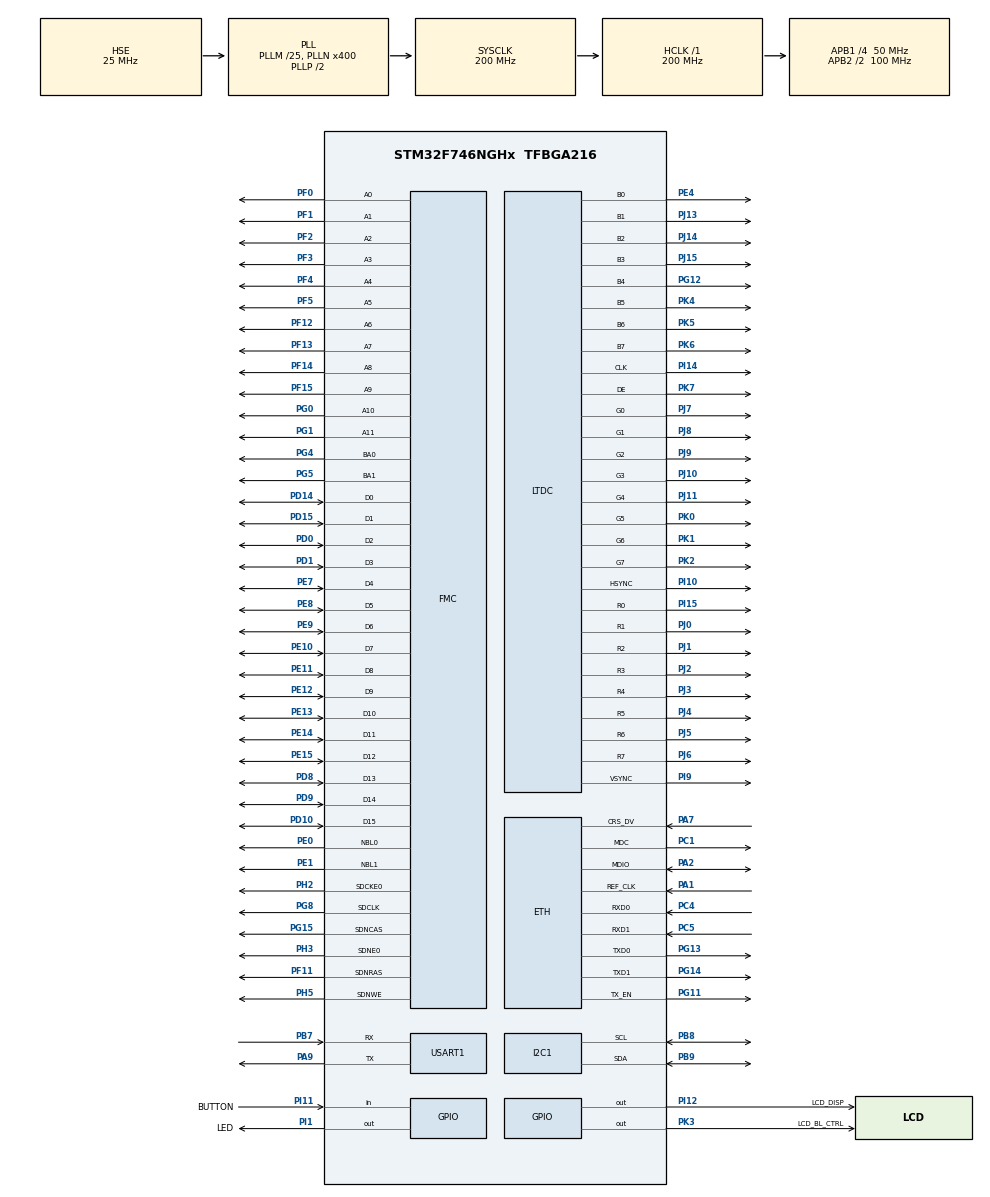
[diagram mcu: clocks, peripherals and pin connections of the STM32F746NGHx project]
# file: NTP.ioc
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ETH.MACAddr=00\:80\:E1\:00\:00\:44
ETH.MediaInterface=HAL_ETH_RMII_MODE
ETH.PhyAddress=0
FREERTOS.Tasks01=app,0,2048,app_main,As weak,NULL,Dynamic,NULL,NULL
FREERTOS.configTOTAL_HEAP_SIZE=15360
FREERTOS.configUSE_NEWLIB_REENTRANT=1
I2C1.Timing=0x00C0EAFF
LTDC.ActiveH=272
LTDC.ActiveW=480
LTDC.Alpha_L0=255
LTDC.Alpha_L1=255
LTDC.BlendingFactor1_L0=LTDC_BLENDING_FACTOR1_PAxCA
LTDC.BlendingFactor1_L1=LTDC_BLENDING_FACTOR1_PAxCA
LTDC.BlendingFactor2_L0=LTDC_BLENDING_FACTOR2_PAxCA
LTDC.BlendingFactor2_L1=LTDC_BLENDING_FACTOR2_PAxCA
LTDC.Green=255
LTDC.HBP=13
LTDC.HFP=32
LTDC.HSync=41
LTDC.ImageHeight_L0=272
LTDC.ImageHeight_L1=272
LTDC.ImageWidth_L0=480
LTDC.ImageWidth_L1=480
LTDC.PixelFormat_L0=LTDC_PIXEL_FORMAT_ARGB1555
LTDC.PixelFormat_L1=LTDC_PIXEL_FORMAT_ARGB1555
LTDC.VSync=10
LTDC.WindowX1_L0=480
LTDC.WindowX1_L1=480
LTDC.WindowY1_L0=272
LTDC.WindowY1_L1=272
LWIP.BSP.number=1
LWIP.LWIP_DNS=1
LWIP.Version=v2.1.2_Cube
LWIP0.BSP.STBoard=false
LWIP0.BSP.api=BSP_COMPONENT_DRIVER
LWIP0.BSP.component=LAN8742
LWIP0.BSP.instance=LAN8742
LWIP0.BSP.name=Driver_PHY
LWIP0.BSP.semaphore=S_LAN8742
LWIP0.BSP.solution=LAN8742
Mcu.Family=STM32F7
Mcu.Name=STM32F746NGHx
Mcu.Package=TFBGA216
NVIC.ETH_IRQn=true\:5\:0\:false\:false\:true\:true\:false\:true\:true
NVIC.PriorityGroup=NVIC_PRIORITYGROUP_4
NVIC.TIM1_UP_TIM10_IRQn=true\:15\:0\:false\:false\:true\:false\:false\:true\:true
NVIC.TimeBase=TIM1_UP_TIM10_IRQn
NVIC.TimeBaseIP=TIM1
PA1.Mode=RMII
PA1.Signal=ETH_REF_CLK
PA2.Mode=RMII
PA2.Signal=ETH_MDIO
PA7.Mode=RMII
PA7.Signal=ETH_CRS_DV
PA9.Mode=Asynchronous
PA9.Signal=USART1_TX
PB7.Mode=Asynchronous
PB7.Signal=USART1_RX
PB8.Mode=I2C
PB8.Signal=I2C1_SCL
PB9.Mode=I2C
PB9.Signal=I2C1_SDA
PC1.Mode=RMII
PC1.Signal=ETH_MDC
PC14/OSC32_IN.Mode=LSE-External-Oscillator
PC14/OSC32_IN.Signal=RCC_OSC32_IN
PC15/OSC32_OUT.Mode=LSE-External-Oscillator
PC15/OSC32_OUT.Signal=RCC_OSC32_OUT
PC4.Mode=RMII
PC4.Signal=ETH_RXD0
PC5.Mode=RMII
PC5.Signal=ETH_RXD1
PD0.Signal=FMC_D2_DA2
PD1.Signal=FMC_D3_DA3
PD10.Signal=FMC_D15_DA15
PD14.Signal=FMC_D0_DA0
PD15.Signal=FMC_D1_DA1
PD8.Signal=FMC_D13_DA13
PD9.Signal=FMC_D14_DA14
PE0.Signal=FMC_NBL0
PE1.Signal=FMC_NBL1
PE10.Signal=FMC_D7_DA7
PE11.Signal=FMC_D8_DA8
PE12.Signal=FMC_D9_DA9
PE13.Signal=FMC_D10_DA10
PE14.Signal=FMC_D11_DA11
PE15.Signal=FMC_D12_DA12
PE4.Mode=RGB888
PE4.Signal=LTDC_B0
PE7.Signal=FMC_D4_DA4
PE8.Signal=FMC_D5_DA5
PE9.Signal=FMC_D6_DA6
PF0.Signal=FMC_A0
PF1.Signal=FMC_A1
PF11.Signal=FMC_SDNRAS
PF12.Signal=FMC_A6
PF13.Signal=FMC_A7
PF14.Signal=FMC_A8
PF15.Signal=FMC_A9
PF2.Signal=FMC_A2
PF3.Signal=FMC_A3
PF4.Signal=FMC_A4
PF5.Signal=FMC_A5
PG0.Signal=FMC_A10
PG1.Signal=FMC_A11
PG11.Mode=RMII
PG11.Signal=ETH_TX_EN
PG12.Mode=RGB888
PG12.Signal=LTDC_B4
PG13.Mode=RMII
PG13.Signal=ETH_TXD0
PG14.Mode=RMII
PG14.Signal=ETH_TXD1
PG15.Signal=FMC_SDNCAS
PG4.Signal=FMC_A14_BA0
PG5.Signal=FMC_A15_BA1
PG8.Signal=FMC_SDCLK
PH0/OSC_IN.Mode=HSE-External-Oscillator
PH0/OSC_IN.Signal=RCC_OSC_IN
PH1/OSC_OUT.Mode=HSE-External-Oscillator
PH1/OSC_OUT.Signal=RCC_OSC_OUT
PH2.Mode=SdramChipSelect1_1
PH2.Signal=FMC_SDCKE0
PH3.Mode=SdramChipSelect1_1
PH3.Signal=FMC_SDNE0
PH5.Signal=FMC_SDNWE
PI1.GPIO_Label=LED
PI1.Signal=GPIO_Output
PI10.Mode=RGB888
PI10.Signal=LTDC_HSYNC
PI11.GPIO_Label=BUTTON
PI11.Signal=GPIO_Input
PI12.GPIO_Label=LCD_DISP
PI12.Signal=GPIO_Output
PI14.Mode=RGB888
PI14.Signal=LTDC_CLK
PI15.Mode=RGB888
PI15.Signal=LTDC_R0
PI9.Mode=RGB888
PI9.Signal=LTDC_VSYNC
PJ0.Mode=RGB888
PJ0.Signal=LTDC_R1
PJ1.Mode=RGB888
PJ1.Signal=LTDC_R2
PJ10.Mode=RGB888
PJ10.Signal=LTDC_G3
PJ11.Mode=RGB888
PJ11.Signal=LTDC_G4
PJ13.Mode=RGB888
PJ13.Signal=LTDC_B1
PJ14.Mode=RGB888
PJ14.Signal=LTDC_B2
PJ15.Mode=RGB888
PJ15.Signal=LTDC_B3
PJ2.Mode=RGB888
PJ2.Signal=LTDC_R3
PJ3.Mode=RGB888
PJ3.Signal=LTDC_R4
PJ4.Mode=RGB888
PJ4.Signal=LTDC_R5
PJ5.Mode=RGB888
PJ5.Signal=LTDC_R6
PJ6.Mode=RGB888
PJ6.Signal=LTDC_R7
PJ7.Mode=RGB888
PJ7.Signal=LTDC_G0
PJ8.Mode=RGB888
PJ8.Signal=LTDC_G1
PJ9.Mode=RGB888
PJ9.Signal=LTDC_G2
PK0.Mode=RGB888
PK0.Signal=LTDC_G5
PK1.Mode=RGB888
PK1.Signal=LTDC_G6
PK2.Mode=RGB888
PK2.Signal=LTDC_G7
PK3.GPIO_Label=LCD_BL_CTRL
PK3.Signal=GPIO_Output
PK4.Mode=RGB888
PK4.Signal=LTDC_B5
PK5.Mode=RGB888
PK5.Signal=LTDC_B6
PK6.Mode=RGB888
PK6.Signal=LTDC_B7
PK7.Mode=RGB888
PK7.Signal=LTDC_DE
ProjectManager.HeapSize=0x200
ProjectManager.StackSize=0x400
ProjectManager.TargetToolchain=STM32CubeIDE
RCC.AHBFreq_Value=200000000
RCC.APB1CLKDivider=RCC_HCLK_DIV4
RCC.APB1Freq_Value=50000000
RCC.APB1TimFreq_Value=100000000
RCC.APB2CLKDivider=RCC_HCLK_DIV2
RCC.APB2Freq_Value=100000000
RCC.APB2TimFreq_Value=200000000
RCC.CortexFreq_Value=200000000
RCC.HCLKFreq_Value=200000000
RCC.HSE_VALUE=25000000
RCC.HSI_VALUE=16000000
RCC.PLLM=25
RCC.PLLN=400
RCC.PLLSAIR=5
RCC.PLLSAIRDiv=RCC_PLLSAIDIVR_4
RCC.PLLSourceVirtual=RCC_PLLSOURCE_HSE
RCC.RTCClockSelection=RCC_RTCCLKSOURCE_LSE
RCC.SYSCLKFreq_VALUE=200000000
RCC.SYSCLKSource=RCC_SYSCLKSOURCE_PLLCLK
RCC.USBFreq_Value=200000000
RCC.VCOOutputFreq_Value=400000000
SH.FMC_A0.0=FMC_A0,12b-sda1
SH.FMC_A1.0=FMC_A1,12b-sda1
SH.FMC_A10.0=FMC_A10,12b-sda1
SH.FMC_A11.0=FMC_A11,12b-sda1
SH.FMC_A14_BA0.0=FMC_BA0,FourSdramBanks1
SH.FMC_A15_BA1.0=FMC_BA1,FourSdramBanks1
SH.FMC_A2.0=FMC_A2,12b-sda1
SH.FMC_A3.0=FMC_A3,12b-sda1
SH.FMC_A4.0=FMC_A4,12b-sda1
SH.FMC_A5.0=FMC_A5,12b-sda1
SH.FMC_A6.0=FMC_A6,12b-sda1
SH.FMC_A7.0=FMC_A7,12b-sda1
SH.FMC_A8.0=FMC_A8,12b-sda1
SH.FMC_A9.0=FMC_A9,12b-sda1
SH.FMC_D0_DA0.0=FMC_D0,sd-16b-d1
SH.FMC_D10_DA10.0=FMC_D10,sd-16b-d1
SH.FMC_D11_DA11.0=FMC_D11,sd-16b-d1
SH.FMC_D12_DA12.0=FMC_D12,sd-16b-d1
SH.FMC_D13_DA13.0=FMC_D13,sd-16b-d1
SH.FMC_D14_DA14.0=FMC_D14,sd-16b-d1
SH.FMC_D15_DA15.0=FMC_D15,sd-16b-d1
SH.FMC_D1_DA1.0=FMC_D1,sd-16b-d1
SH.FMC_D2_DA2.0=FMC_D2,sd-16b-d1
SH.FMC_D3_DA3.0=FMC_D3,sd-16b-d1
SH.FMC_D4_DA4.0=FMC_D4,sd-16b-d1
SH.FMC_D5_DA5.0=FMC_D5,sd-16b-d1
SH.FMC_D6_DA6.0=FMC_D6,sd-16b-d1
SH.FMC_D7_DA7.0=FMC_D7,sd-16b-d1
SH.FMC_D8_DA8.0=FMC_D8,sd-16b-d1
SH.FMC_D9_DA9.0=FMC_D9,sd-16b-d1
SH.FMC_NBL0.0=FMC_NBL0,Sd2ByteEnable1
SH.FMC_NBL1.0=FMC_NBL1,Sd2ByteEnable1
SH.FMC_SDCLK.0=FMC_SDCLK,12b-sda1
SH.FMC_SDNCAS.0=FMC_SDNCAS,12b-sda1
SH.FMC_SDNRAS.0=FMC_SDNRAS,12b-sda1
SH.FMC_SDNWE.0=FMC_SDNWE,12b-sda1
USART1.VirtualMode=VM_ASYNC
USART1.VirtualMode-Asynchronous=VM_ASYNC
USART1.WordLength=WORDLENGTH_8B
VP_DMA2D_VS_DMA2D.Mode=DMA2D_Activate
VP_FREERTOS_VS_CMSIS_V1.Mode=CMSIS_V1
VP_LWIP_VS_Enabled.Mode=Enabled
VP_RTC_VS_RTC_Activate.Mode=RTC_Enabled
VP_SYS_VS_tim1.Mode=TIM1
board=STM32F746G-DISCO

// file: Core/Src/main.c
/* USER CODE BEGIN Header */
/**
 ******************************************************************************
 * @file           : main.c
 * @brief          : Main program body
 ******************************************************************************
 * @attention
 *
 * Copyright (c) 2022 STMicroelectronics.
 * All rights reserved.
 *
 * This software is licensed under terms that can be found in the LICENSE file
 * in the root directory of this software component.
 * If no LICENSE file comes with this software, it is provided AS-IS.
 *
 ******************************************************************************
 */
/* USER CODE END Header */
#include "main.h"
#include "cmsis_os.h"
#include "lwip.h"

/* USER CODE BEGIN Includes */
#include "NTP.h"
#include "stm32746g_discovery_lcd.h"
/* USER CODE END Includes */

DMA2D_HandleTypeDef hdma2d;

I2C_HandleTypeDef hi2c1;

LTDC_HandleTypeDef hltdc;

RTC_HandleTypeDef hrtc;

UART_HandleTypeDef huart1;

SDRAM_HandleTypeDef hsdram1;

osThreadId appHandle;

void SystemClock_Config(void);
static void MX_GPIO_Init(void);
static void MX_LTDC_Init(void);
static void MX_USART1_UART_Init(void);
static void MX_DMA2D_Init(void);
static void MX_FMC_Init(void);
static void MX_RTC_Init(void);
static void MX_I2C1_Init(void);
void app_main(void const * argument);

int main(void)
{

  /* MCU Configuration--------------------------------------------------------*/

  /* Reset of all peripherals, Initializes the Flash interface and the Systick. */
  HAL_Init();

  /* Configure the system clock */
  SystemClock_Config();

  /* Initialize all configured peripherals */
  MX_GPIO_Init();
  MX_LTDC_Init();
  MX_USART1_UART_Init();
  MX_DMA2D_Init();
  MX_FMC_Init();
  MX_RTC_Init();
  MX_I2C1_Init();
  /* USER CODE BEGIN 2 */
  ip_addr_t ip;
  /* set the default dns server for the NTP client*/
  debugln("Setting default dns server");
  IP4_ADDR(&ip, 8, 8, 8, 8);
  dns_setserver(0, &ip);

  /* Backlight */
  HAL_GPIO_WritePin(LCD_BL_CTRL_GPIO_Port, LCD_BL_CTRL_Pin, GPIO_PIN_SET);
  /* Assert display enable LCD_DISP pin */
  HAL_GPIO_WritePin(LCD_DISP_GPIO_Port, LCD_DISP_Pin, GPIO_PIN_SET);

  BSP_LCD_Init();
  BSP_LCD_LayerDefaultInit(1, LCD_FB_START_ADDRESS);
  BSP_LCD_LayerDefaultInit(0, LCD_FB_START_ADDRESS + (480 * 272 * 4));
  /* Enable the LCD */
  BSP_LCD_DisplayOn();
  /* Select the LCD Background Layer  */
  BSP_LCD_SelectLayer(0);
  /* Clear the Background Layer */
  BSP_LCD_Clear(LCD_COLOR_BLACK);
  BSP_LCD_SelectLayer(1);
  /* Clear the foreground Layer */
  BSP_LCD_Clear(LCD_COLOR_TRANSPARENT);
  /* Some sign */
  BSP_LCD_SetTextColor(LCD_COLOR_WHITE);
  BSP_LCD_SetBackColor(LCD_COLOR_BLACK);
  BSP_LCD_SetFont(&Font12);
  BSP_LCD_DisplayStringAt(0, 0, (uint8_t*) "Initializing...", CENTER_MODE);
  printf(CLEAR_SCREEN);
  debugln("Display is initialized");
  /* USER CODE END 2 */

  /* USER CODE BEGIN RTOS_MUTEX */
  debugln("Kernel initialized");
  /* add mutexes, ... */
  /* USER CODE END RTOS_MUTEX */

  /* Create the thread(s) */
  /* definition and creation of app */
  osThreadDef(app, app_main, osPriorityNormal, 0, 2048);
  appHandle = osThreadCreate(osThread(app), NULL);

  /* USER CODE BEGIN RTOS_THREADS */
  debugln("appHandle created");
  /* add threads, ... */
  /* USER CODE END RTOS_THREADS */

  /* Start scheduler */
  osKernelStart();

  /* We should never get here as control is now taken by the scheduler */
  /* Infinite loop */
	while (1)
	{

	}
}

void SystemClock_Config(void)
{
  RCC_OscInitTypeDef RCC_OscInitStruct = {0};
  RCC_ClkInitTypeDef RCC_ClkInitStruct = {0};

  /** Configure LSE Drive Capability
  */
  HAL_PWR_EnableBkUpAccess();
  __HAL_RCC_LSEDRIVE_CONFIG(RCC_LSEDRIVE_LOW);

  /** Configure the main internal regulator output voltage
  */
  __HAL_RCC_PWR_CLK_ENABLE();
  __HAL_PWR_VOLTAGESCALING_CONFIG(PWR_REGULATOR_VOLTAGE_SCALE1);

  /** Initializes the RCC Oscillators according to the specified parameters
  * in the RCC_OscInitTypeDef structure.
  */
  RCC_OscInitStruct.OscillatorType = RCC_OSCILLATORTYPE_HSE|RCC_OSCILLATORTYPE_LSE;
  RCC_OscInitStruct.HSEState = RCC_HSE_ON;
  RCC_OscInitStruct.LSEState = RCC_LSE_ON;
  RCC_OscInitStruct.PLL.PLLState = RCC_PLL_ON;
  RCC_OscInitStruct.PLL.PLLSource = RCC_PLLSOURCE_HSE;
  RCC_OscInitStruct.PLL.PLLM = 25;
  RCC_OscInitStruct.PLL.PLLN = 400;
  RCC_OscInitStruct.PLL.PLLP = RCC_PLLP_DIV2;
  RCC_OscInitStruct.PLL.PLLQ = 2;
  if (HAL_RCC_OscConfig(&RCC_OscInitStruct) != HAL_OK)
  {
    Error_Handler();
  }

  /** Activate the Over-Drive mode
  */
  if (HAL_PWREx_EnableOverDrive() != HAL_OK)
  {
    Error_Handler();
  }

  /** Initializes the CPU, AHB and APB buses clocks
  */
  RCC_ClkInitStruct.ClockType = RCC_CLOCKTYPE_HCLK|RCC_CLOCKTYPE_SYSCLK
                              |RCC_CLOCKTYPE_PCLK1|RCC_CLOCKTYPE_PCLK2;
  RCC_ClkInitStruct.SYSCLKSource = RCC_SYSCLKSOURCE_PLLCLK;
  RCC_ClkInitStruct.AHBCLKDivider = RCC_SYSCLK_DIV1;
  RCC_ClkInitStruct.APB1CLKDivider = RCC_HCLK_DIV4;
  RCC_ClkInitStruct.APB2CLKDivider = RCC_HCLK_DIV2;

  if (HAL_RCC_ClockConfig(&RCC_ClkInitStruct, FLASH_LATENCY_6) != HAL_OK)
  {
    Error_Handler();
  }
}

static void MX_DMA2D_Init(void)
{

  hdma2d.Instance = DMA2D;
  hdma2d.Init.Mode = DMA2D_M2M;
  hdma2d.Init.ColorMode = DMA2D_OUTPUT_ARGB8888;
  hdma2d.Init.OutputOffset = 0;
  hdma2d.LayerCfg[1].InputOffset = 0;
  hdma2d.LayerCfg[1].InputColorMode = DMA2D_INPUT_ARGB8888;
  hdma2d.LayerCfg[1].AlphaMode = DMA2D_NO_MODIF_ALPHA;
  hdma2d.LayerCfg[1].InputAlpha = 0;
  if (HAL_DMA2D_Init(&hdma2d) != HAL_OK)
  {
    Error_Handler();
  }
  if (HAL_DMA2D_ConfigLayer(&hdma2d, 1) != HAL_OK)
  {
    Error_Handler();
  }

}

static void MX_I2C1_Init(void)
{

  hi2c1.Instance = I2C1;
  hi2c1.Init.Timing = 0x00C0EAFF;
  hi2c1.Init.OwnAddress1 = 0;
  hi2c1.Init.AddressingMode = I2C_ADDRESSINGMODE_7BIT;
  hi2c1.Init.DualAddressMode = I2C_DUALADDRESS_DISABLE;
  hi2c1.Init.OwnAddress2 = 0;
  hi2c1.Init.OwnAddress2Masks = I2C_OA2_NOMASK;
  hi2c1.Init.GeneralCallMode = I2C_GENERALCALL_DISABLE;
  hi2c1.Init.NoStretchMode = I2C_NOSTRETCH_DISABLE;
  if (HAL_I2C_Init(&hi2c1) != HAL_OK)
  {
    Error_Handler();
  }

  /** Configure Analogue filter
  */
  if (HAL_I2CEx_ConfigAnalogFilter(&hi2c1, I2C_ANALOGFILTER_ENABLE) != HAL_OK)
  {
    Error_Handler();
  }

  /** Configure Digital filter
  */
  if (HAL_I2CEx_ConfigDigitalFilter(&hi2c1, 0) != HAL_OK)
  {
    Error_Handler();
  }

}

static void MX_LTDC_Init(void)
{

  LTDC_LayerCfgTypeDef pLayerCfg = {0};
  LTDC_LayerCfgTypeDef pLayerCfg1 = {0};

  hltdc.Instance = LTDC;
  hltdc.Init.HSPolarity = LTDC_HSPOLARITY_AL;
  hltdc.Init.VSPolarity = LTDC_VSPOLARITY_AL;
  hltdc.Init.DEPolarity = LTDC_DEPOLARITY_AL;
  hltdc.Init.PCPolarity = LTDC_PCPOLARITY_IPC;
  hltdc.Init.HorizontalSync = 40;
  hltdc.Init.VerticalSync = 9;
  hltdc.Init.AccumulatedHBP = 53;
  hltdc.Init.AccumulatedVBP = 11;
  hltdc.Init.AccumulatedActiveW = 533;
  hltdc.Init.AccumulatedActiveH = 283;
  hltdc.Init.TotalWidth = 565;
  hltdc.Init.TotalHeigh = 285;
  hltdc.Init.Backcolor.Blue = 0;
  hltdc.Init.Backcolor.Green = 255;
  hltdc.Init.Backcolor.Red = 0;
  if (HAL_LTDC_Init(&hltdc) != HAL_OK)
  {
    Error_Handler();
  }
  pLayerCfg.WindowX0 = 0;
  pLayerCfg.WindowX1 = 480;
  pLayerCfg.WindowY0 = 0;
  pLayerCfg.WindowY1 = 272;
  pLayerCfg.PixelFormat = LTDC_PIXEL_FORMAT_ARGB1555;
  pLayerCfg.Alpha = 255;
  pLayerCfg.Alpha0 = 0;
  pLayerCfg.BlendingFactor1 = LTDC_BLENDING_FACTOR1_PAxCA;
  pLayerCfg.BlendingFactor2 = LTDC_BLENDING_FACTOR2_PAxCA;
  pLayerCfg.FBStartAdress = 0;
  pLayerCfg.ImageWidth = 480;
  pLayerCfg.ImageHeight = 272;
  pLayerCfg.Backcolor.Blue = 0;
  pLayerCfg.Backcolor.Green = 0;
  pLayerCfg.Backcolor.Red = 0;
  if (HAL_LTDC_ConfigLayer(&hltdc, &pLayerCfg, 0) != HAL_OK)
  {
    Error_Handler();
  }
  pLayerCfg1.WindowX0 = 0;
  pLayerCfg1.WindowX1 = 480;
  pLayerCfg1.WindowY0 = 0;
  pLayerCfg1.WindowY1 = 272;
  pLayerCfg1.PixelFormat = LTDC_PIXEL_FORMAT_ARGB1555;
  pLayerCfg1.Alpha = 255;
  pLayerCfg1.Alpha0 = 0;
  pLayerCfg1.BlendingFactor1 = LTDC_BLENDING_FACTOR1_PAxCA;
  pLayerCfg1.BlendingFactor2 = LTDC_BLENDING_FACTOR2_PAxCA;
  pLayerCfg1.FBStartAdress = 0;
  pLayerCfg1.ImageWidth = 480;
  pLayerCfg1.ImageHeight = 272;
  pLayerCfg1.Backcolor.Blue = 0;
  pLayerCfg1.Backcolor.Green = 0;
  pLayerCfg1.Backcolor.Red = 0;
  if (HAL_LTDC_ConfigLayer(&hltdc, &pLayerCfg1, 1) != HAL_OK)
  {
    Error_Handler();
  }

}

static void MX_RTC_Init(void)
{

  /** Initialize RTC Only
  */
  hrtc.Instance = RTC;
  hrtc.Init.HourFormat = RTC_HOURFORMAT_24;
  hrtc.Init.AsynchPrediv = 127;
  hrtc.Init.SynchPrediv = 255;
  hrtc.Init.OutPut = RTC_OUTPUT_DISABLE;
  hrtc.Init.OutPutPolarity = RTC_OUTPUT_POLARITY_HIGH;
  hrtc.Init.OutPutType = RTC_OUTPUT_TYPE_OPENDRAIN;
  if (HAL_RTC_Init(&hrtc) != HAL_OK)
  {
    Error_Handler();
  }

}

static void MX_USART1_UART_Init(void)
{

  huart1.Instance = USART1;
  huart1.Init.BaudRate = 115200;
  huart1.Init.WordLength = UART_WORDLENGTH_8B;
  huart1.Init.StopBits = UART_STOPBITS_1;
  huart1.Init.Parity = UART_PARITY_NONE;
  huart1.Init.Mode = UART_MODE_TX_RX;
  huart1.Init.HwFlowCtl = UART_HWCONTROL_NONE;
  huart1.Init.OverSampling = UART_OVERSAMPLING_16;
  huart1.Init.OneBitSampling = UART_ONE_BIT_SAMPLE_DISABLE;
  huart1.AdvancedInit.AdvFeatureInit = UART_ADVFEATURE_NO_INIT;
  if (HAL_UART_Init(&huart1) != HAL_OK)
  {
    Error_Handler();
  }

}

/* FMC initialization function */
static void MX_FMC_Init(void)
{

  FMC_SDRAM_TimingTypeDef SdramTiming = {0};

  /** Perform the SDRAM1 memory initialization sequence
  */
  hsdram1.Instance = FMC_SDRAM_DEVICE;
  /* hsdram1.Init */
  hsdram1.Init.SDBank = FMC_SDRAM_BANK1;
  hsdram1.Init.ColumnBitsNumber = FMC_SDRAM_COLUMN_BITS_NUM_8;
  hsdram1.Init.RowBitsNumber = FMC_SDRAM_ROW_BITS_NUM_12;
  hsdram1.Init.MemoryDataWidth = FMC_SDRAM_MEM_BUS_WIDTH_16;
  hsdram1.Init.InternalBankNumber = FMC_SDRAM_INTERN_BANKS_NUM_4;
  hsdram1.Init.CASLatency = FMC_SDRAM_CAS_LATENCY_1;
  hsdram1.Init.WriteProtection = FMC_SDRAM_WRITE_PROTECTION_DISABLE;
  hsdram1.Init.SDClockPeriod = FMC_SDRAM_CLOCK_DISABLE;
  hsdram1.Init.ReadBurst = FMC_SDRAM_RBURST_DISABLE;
  hsdram1.Init.ReadPipeDelay = FMC_SDRAM_RPIPE_DELAY_0;
  /* SdramTiming */
  SdramTiming.LoadToActiveDelay = 16;
  SdramTiming.ExitSelfRefreshDelay = 16;
  SdramTiming.SelfRefreshTime = 16;
  SdramTiming.RowCycleDelay = 16;
  SdramTiming.WriteRecoveryTime = 16;
  SdramTiming.RPDelay = 16;
  SdramTiming.RCDDelay = 16;

  if (HAL_SDRAM_Init(&hsdram1, &SdramTiming) != HAL_OK)
  {
    Error_Handler( );
  }

}

static void MX_GPIO_Init(void)
{
  GPIO_InitTypeDef GPIO_InitStruct = {0};

  /* GPIO Ports Clock Enable */
  __HAL_RCC_GPIOE_CLK_ENABLE();
  __HAL_RCC_GPIOG_CLK_ENABLE();
  __HAL_RCC_GPIOB_CLK_ENABLE();
  __HAL_RCC_GPIOJ_CLK_ENABLE();
  __HAL_RCC_GPIOD_CLK_ENABLE();
  __HAL_RCC_GPIOK_CLK_ENABLE();
  __HAL_RCC_GPIOF_CLK_ENABLE();
  __HAL_RCC_GPIOI_CLK_ENABLE();
  __HAL_RCC_GPIOC_CLK_ENABLE();
  __HAL_RCC_GPIOA_CLK_ENABLE();
  __HAL_RCC_GPIOH_CLK_ENABLE();

  /*Configure GPIO pin Output Level */
  HAL_GPIO_WritePin(LCD_BL_CTRL_GPIO_Port, LCD_BL_CTRL_Pin, GPIO_PIN_RESET);

  /*Configure GPIO pin Output Level */
  HAL_GPIO_WritePin(GPIOI, LED_Pin|LCD_DISP_Pin, GPIO_PIN_RESET);

  /*Configure GPIO pin : LCD_BL_CTRL_Pin */
  GPIO_InitStruct.Pin = LCD_BL_CTRL_Pin;
  GPIO_InitStruct.Mode = GPIO_MODE_OUTPUT_PP;
  GPIO_InitStruct.Pull = GPIO_NOPULL;
  GPIO_InitStruct.Speed = GPIO_SPEED_FREQ_LOW;
  HAL_GPIO_Init(LCD_BL_CTRL_GPIO_Port, &GPIO_InitStruct);

  /*Configure GPIO pins : LED_Pin LCD_DISP_Pin */
  GPIO_InitStruct.Pin = LED_Pin|LCD_DISP_Pin;
  GPIO_InitStruct.Mode = GPIO_MODE_OUTPUT_PP;
  GPIO_InitStruct.Pull = GPIO_NOPULL;
  GPIO_InitStruct.Speed = GPIO_SPEED_FREQ_LOW;
  HAL_GPIO_Init(GPIOI, &GPIO_InitStruct);

  /*Configure GPIO pin : BUTTON_Pin */
  GPIO_InitStruct.Pin = BUTTON_Pin;
  GPIO_InitStruct.Mode = GPIO_MODE_INPUT;
  GPIO_InitStruct.Pull = GPIO_NOPULL;
  HAL_GPIO_Init(BUTTON_GPIO_Port, &GPIO_InitStruct);

}

__weak void app_main(void const * argument)
{
  /* init code for LWIP */
  MX_LWIP_Init();
  for(;;)
  {
    osDelay(1);
  }
}

void HAL_TIM_PeriodElapsedCallback(TIM_HandleTypeDef *htim)
{
  if (htim->Instance == TIM1) {
    HAL_IncTick();
  }
}

void Error_Handler(void)
{
	__disable_irq();
	while (1)
	{
	}
}
